# BS2X register map
File version: 0.1
CPU: other r0p0, little endian, MPU, FPU, 3 interrupt priority bits
Registers are 32-bit, read-write, reset 0x0 unless marked. A register's access mark holds for its fields unless they carry their own. Offsets are from the block's base; [hi:lo] are bit positions; {n}, {i} and the like mark numbered series.

## WDT — Watchdog timer (v151)
Base 0x52003000
0x00 WDT_LOCK — Watchdog lock register
  [31:0] wdt_lock wo — Write 0x5A5A5A5A to unlock, other values lock
0x04 WDT_LOAD — Watchdog load value
  [31:8] wdt_load — Load count value (24-bit, low 8 bits reserved)
0x08 WDT_RESTART — Watchdog restart register
  [31:0] wdt_restart wo — Write anything except 0x5A5A5A5A to restart counter
0x0C WDT_EOI — Watchdog interrupt clear (read to clear)
  [0] wdt_eoi ro — Read to clear watchdog interrupt
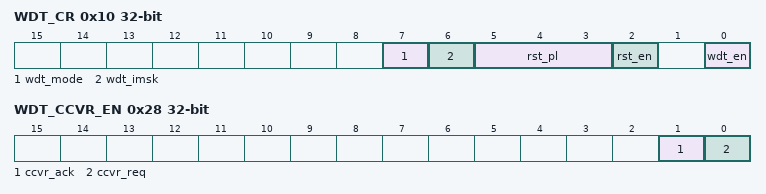
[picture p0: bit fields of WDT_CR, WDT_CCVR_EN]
0x10 WDT_CR — Watchdog control register
  [7] wdt_mode — Mode: 0=one interrupt then reset; 1=two interrupts then reset
    0=Mode1 (Single interrupt then reset); 1=Mode2 (Two interrupts then reset)
  [6] wdt_imsk — Interrupt mask: 0=unmasked; 1=masked
  [5:3] rst_pl — Reset pulse length: 000=2 clocks; up to 111=256 clocks
  [2] rst_en — Reset enable: 0=no reset on timeout; 1=reset on timeout
  [0] wdt_en — Watchdog enable: 0=disabled; 1=enabled
0x14 WDT_CNT — Watchdog current counter value
  [31:0] wdt_cnt ro — Current counter value
0x18 WDT_RAW_INTR — Watchdog raw interrupt status
  [0] wdt_raw_intr ro — Raw interrupt status
0x1C WDT_INTR — Watchdog interrupt status (masked)
  [0] wdt_intr ro — Interrupt status after mask
0x20 WDT_LPIF_STATE — Watchdog low power state
  [2:0] wdt_lpif_state ro — Low power interface state
0x24 WDT_STATUS — Watchdog status
  [0] wdt_status ro — Status: 0=busy; 1=free
0x28 WDT_CCVR_EN — Watchdog counter value request
  [1] ccvr_ack ro — Acknowledge: 1=counter value valid
  [0] ccvr_req wo — Write 1 to request current counter value

## TCXO — TCXO 64-bit free-running counter (v150)
Base 0x57000200
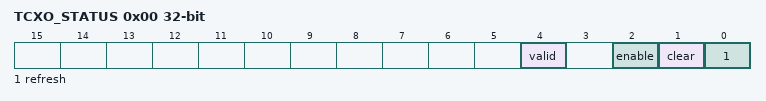
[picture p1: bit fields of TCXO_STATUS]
0x00 TCXO_STATUS — TCXO status and control register
  [4] valid ro — TCXO count value valid flag
  [2] enable — TCXO count enable: 1=enable counting
  [1] clear — TCXO count clear: 1=clear counter
  [0] refresh — TCXO count refresh: 1=trigger count latch
{0x4+4i} TCXO_COUNT{i} (i=0..3) — TCXO count bits [{16i+15}:{16i}]
  [15:0] count{i} ro — Counter value bits [{16i+15}:{16i}]

## I2C0 — I2C master controller (DesignWare-compatible v151)
Base 0x52083000
Same registers: I2C1 0x52084000
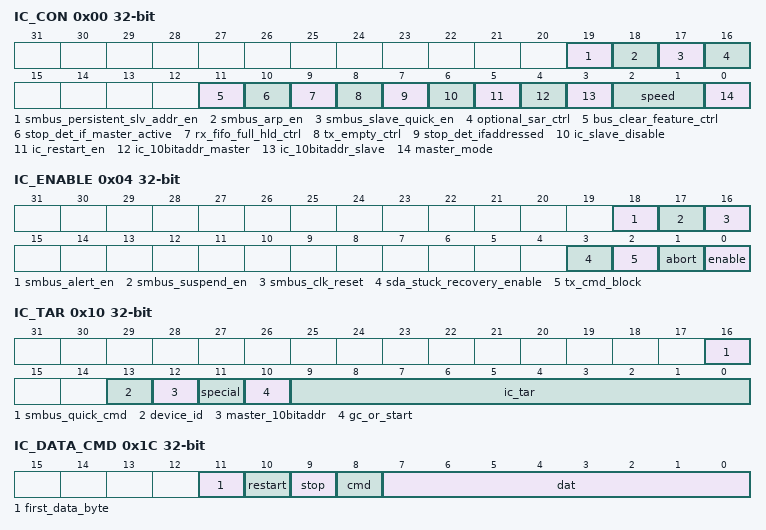
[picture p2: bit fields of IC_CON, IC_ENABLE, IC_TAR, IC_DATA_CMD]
0x00 IC_CON — con
  [19] smbus_persistent_slv_addr_en, [18] smbus_arp_en, [17] smbus_slave_quick_en, [16] optional_sar_ctrl, [11] bus_clear_feature_ctrl, [10] stop_det_if_master_active, [9] rx_fifo_full_hld_ctrl, [8] tx_empty_ctrl, [7] stop_det_ifaddressed, [6] ic_slave_disable, [5] ic_restart_en, [4] ic_10bitaddr_master, [3] ic_10bitaddr_slave, [2:1] speed, [0] master_mode
0x04 IC_ENABLE — enable
  [18] smbus_alert_en, [17] smbus_suspend_en, [16] smbus_clk_reset, [3] sda_stuck_recovery_enable, [2] tx_cmd_block, [1] abort, [0] enable
0x10 IC_TAR — tar
  [16] smbus_quick_cmd, [13] device_id, [12] master_10bitaddr, [11] special, [10] gc_or_start, [9:0] ic_tar
0x14 IC_SAR — sar
  [9:0] ic_sar
0x18 IC_HS_MADDR — hs_maddr
  [2:0] ic_hs_mar
0x1C IC_DATA_CMD — data_cmd
  [11] first_data_byte, [10] restart, [9] stop, [8] cmd, [7:0] dat
0x30 IC_SS_SCL_HCNT — ss_scl_hcnt
  [15:0] ic_ss_scl_hcnt
0x34 IC_SS_SCL_LCNT — ss_scl_lcnt
  [15:0] ic_ss_scl_lcnt
0x3C IC_FS_SCL_HCNT — fs_scl_hcnt
  [15:0] ic_fs_scl_hcnt
0x40 IC_FS_SCL_LCNT — fs_scl_lcnt
  [15:0] ic_fs_scl_lcnt
0x44 IC_HS_SCL_HCNT — hs_scl_hcnt
  [15:0] ic_hs_scl_hcnt
0x48 IC_HS_SCL_LCNT — hs_scl_lcnt
  [15:0] ic_hs_scl_lcnt
0x50 IC_RX_TL — rx_tl
  [7:0] rx_tl
0x54 IC_TX_TL — tx_tl
  [7:0] tx_tl
0x58 IC_SLAVE_DATA_NACK_ONLY — slave_data_nack_only
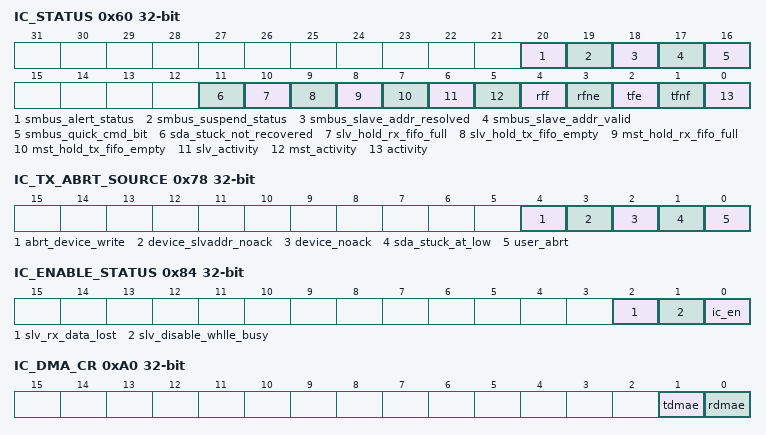
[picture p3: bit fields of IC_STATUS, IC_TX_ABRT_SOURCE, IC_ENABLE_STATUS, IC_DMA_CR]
0x60 IC_STATUS — status
  [20] smbus_alert_status, [19] smbus_suspend_status, [18] smbus_slave_addr_resolved, [17] smbus_slave_addr_valid, [16] smbus_quick_cmd_bit, [11] sda_stuck_not_recovered, [10] slv_hold_rx_fifo_full, [9] slv_hold_tx_fifo_empty, [8] mst_hold_rx_fifo_full, [7] mst_hold_tx_fifo_empty, [6] slv_activity, [5] mst_activity, [4] rff, [3] rfne, [2] tfe, [1] tfnf, [0] activity
0x64 IC_TXFLR — txflr
0x68 IC_RXFLR — rxflr
0x6C IC_SDA_RX_HOLD — sda_rx_hold
  [7:0] sda_rx_hold
0x70 IC_SDA_TX_HOLD — sda_tx_hold
  [15:0] sda_tx_hold
0x74 IC_TX_FLUSH_CNT — tx_flush_cnt
  [8:0] tx_flush_cnt
0x78 IC_TX_ABRT_SOURCE — tx_abrt_source
  [4] abrt_device_write, [3] device_slvaddr_noack, [2] device_noack, [1] sda_stuck_at_low, [0] user_abrt
0x7C IC_TX_ABRT_SLV_INTX — tx_abrt_slv_intx
0x80 IC_ACK_GENERAL_CALL — ack_general_call
0x84 IC_ENABLE_STATUS — enable_status
  [2] slv_rx_data_lost, [1] slv_disable_whlle_busy, [0] ic_en
0xA0 IC_DMA_CR — dma_cr
  [1] tdmae, [0] rdmae
0xA4 IC_DMA_TDLR — dma_tdlr
0xA8 IC_DMA_RDLR — dma_rdlr
0xAC IC_SDA_SETUP — sda_setup
  [7:0] sda_setup
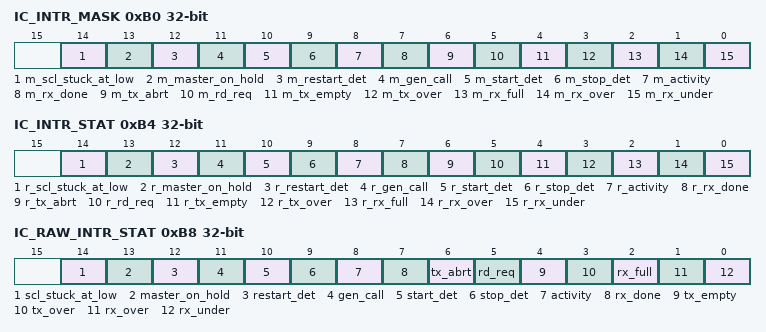
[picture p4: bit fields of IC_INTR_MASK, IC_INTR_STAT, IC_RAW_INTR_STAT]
0xB0 IC_INTR_MASK — intr_mask
  [14] m_scl_stuck_at_low, [13] m_master_on_hold, [12] m_restart_det, [11] m_gen_call, [10] m_start_det, [9] m_stop_det, [8] m_activity, [7] m_rx_done, [6] m_tx_abrt, [5] m_rd_req, [4] m_tx_empty, [3] m_tx_over, [2] m_rx_full, [1] m_rx_over, [0] m_rx_under
0xB4 IC_INTR_STAT — intr_stat
  [14] r_scl_stuck_at_low, [13] r_master_on_hold, [12] r_restart_det, [11] r_gen_call, [10] r_start_det, [9] r_stop_det, [8] r_activity, [7] r_rx_done, [6] r_tx_abrt, [5] r_rd_req, [4] r_tx_empty, [3] r_tx_over, [2] r_rx_full, [1] r_rx_over, [0] r_rx_under
0xB8 IC_RAW_INTR_STAT — raw_intr_stat
  [14] scl_stuck_at_low, [13] master_on_hold, [12] restart_det, [11] gen_call, [10] start_det, [9] stop_det, [8] activity, [7] rx_done, [6] tx_abrt, [5] rd_req, [4] tx_empty, [3] tx_over, [2] rx_full, [1] rx_over, [0] rx_under
0xBC IC_INTR_STAT_ALL — intr_stat_all
0xC0 IC_CLR_INTR — clr_intr
0xC4 IC_CLR_INT — clr_int
  [0] clr_int
